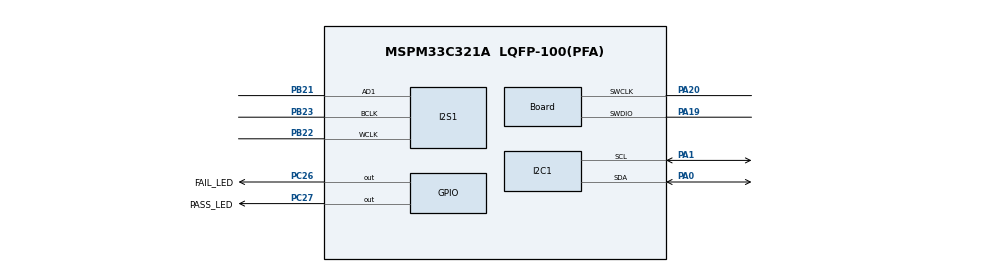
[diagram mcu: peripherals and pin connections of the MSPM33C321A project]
//@cliArgs --device "MSPM33C321A" --package "LQFP-100(PFA)" --part "Default"
//@v2CliArgs --device "MSPM33C321A" --package "LQFP-100(PFA)"
// @cliArgs --board /ti/boards/LP_MSPM33C321A --rtos nortos

/**
 * Import the modules used in this configuration.
 */
const DMA    = scripting.addModule("/ti/driverlib/DMA", {}, false);
const DMA1   = DMA.addInstance();
const GPIO   = scripting.addModule("/ti/driverlib/GPIO", {}, false);
const GPIO1  = GPIO.addInstance();
const I2C    = scripting.addModule("/ti/driverlib/I2C", {}, false);
const I2C1   = I2C.addInstance();
const I2S    = scripting.addModule("/ti/driverlib/I2S", {}, false);
const I2S1   = I2S.addInstance();
const SYSCTL = scripting.addModule("/ti/driverlib/SYSCTL");

/**
 * Write custom configuration values to the imported modules.
 */
DMA1.$name = "DMA0";

const Board                       = scripting.addModule("/ti/driverlib/Board", {}, false);
Board.peripheral.$assign          = "DEBUGSS";
Board.peripheral.swclkPin.$assign = "PA20";
Board.peripheral.swdioPin.$assign = "PA19";

GPIO1.$name                                 = "GPIO_LEDS";
GPIO1.associatedPins.create(2);
GPIO1.associatedPins[0].$name               = "FAIL_LED";
GPIO1.associatedPins[0].assignedPort        = "PORTC";
GPIO1.associatedPins[0].assignedPortSegment = "Upper";
GPIO1.associatedPins[0].assignedPin         = "26";
GPIO1.associatedPins[0].launchPadShortcut   = "LED2RedEn";
GPIO1.associatedPins[0].pin.$assign         = "PC26";
GPIO1.associatedPins[1].$name               = "PASS_LED";
GPIO1.associatedPins[1].launchPadShortcut   = "LED2GreenEn";
GPIO1.associatedPins[1].pin.$assign         = "PC27";

I2C1.basicTargetAddress                = 0x50;
I2C1.advTargetTXFIFOTRIG               = "ALMOST_EMPTY";
I2C1.$name                             = "I2C";
I2C1.basicEnableController             = true;
I2C1.basicControllerStandardBusSpeed   = "Fast";
I2C1.peripheral.$assign                = "UC1_0";
I2C1.peripheral.sdaPin.$assign         = "PA0";
I2C1.peripheral.sclPin.$assign         = "PA1";
I2C1.sdaPinConfig.$name                = "ti_driverlib_gpio_GPIOPinGeneric0";
I2C1.sdaPinConfig.hideOutputInversion  = scripting.forceWrite(false);
I2C1.sdaPinConfig.onlyInternalResistor = scripting.forceWrite(false);
I2C1.sdaPinConfig.passedPeripheralType = scripting.forceWrite("Digital");
I2C1.sdaPinConfig.enableConfig         = true;
I2C1.sdaPinConfig.internalResistor     = "PULL_UP";
I2C1.sclPinConfig.$name                = "ti_driverlib_gpio_GPIOPinGeneric1";
I2C1.sclPinConfig.hideOutputInversion  = scripting.forceWrite(false);
I2C1.sclPinConfig.onlyInternalResistor = scripting.forceWrite(false);
I2C1.sclPinConfig.passedPeripheralType = scripting.forceWrite("Digital");
I2C1.sclPinConfig.enableConfig         = true;
I2C1.sclPinConfig.internalResistor     = "PULL_UP";

I2S1.$name                                 = "I2S_0";
I2S1.wclkInvert                            = true;
I2S1.phase                                 = "DUAL";
I2S1.dataDelay                             = "ONE";
I2S1.wordBaudClockSource                   = "INTERNAL";
I2S1.wclkPhase                             = "DUAL";
I2S1.dataPin1Enable                        = true;
I2S1.dataPin1Direction                     = "OUTPUT";
I2S1.wclkDivider                           = 16;
I2S1.bclkDivider                           = 23;
I2S1.sampleWordLength                      = 16;
I2S1.enabledDMAEvent2Triggers              = "DL_I2S_DMA_INTERRUPT_TX_TRIGGER";
I2S1.enabledInterrupts                     = ["DMA_DONE_TX"];
I2S1.peripheral.$assign                    = "I2S1";
I2S1.peripheral.AD1Pin.$assign             = "PB21";
I2S1.peripheral.BCLKPin.$assign            = "PB23";
I2S1.peripheral.WCLKPin.$assign            = "PB22";
I2S1.DMA_CHANNEL_EVENT2.$name              = "CH0";
I2S1.DMA_CHANNEL_EVENT2.srcLength          = "HALF_WORD";
I2S1.DMA_CHANNEL_EVENT2.dstLength          = "HALF_WORD";
I2S1.DMA_CHANNEL_EVENT2.srcIncrement       = "INCREMENT";
I2S1.DMA_CHANNEL_EVENT2.addressMode        = "b2f";
I2S1.DMA_CHANNEL_EVENT2.transferMode       = "FULL_CH_REPEAT_SINGLE";
I2S1.DMA_CHANNEL_EVENT2.peripheral.$assign = "DMA0_CH0";

SYSCTL.forceDefaultClkConfig = true;
SYSCTL.peripheral.$assign    = "SYSCTL";

const ProjectConfig              = scripting.addModule("/ti/project_config/ProjectConfig", {}, false);
ProjectConfig.migrationCondition = true;
ProjectConfig.genLinker          = true;
ProjectConfig.genStartup         = true;
ProjectConfig.genOpts            = true;
ProjectConfig.genLibs            = true;
